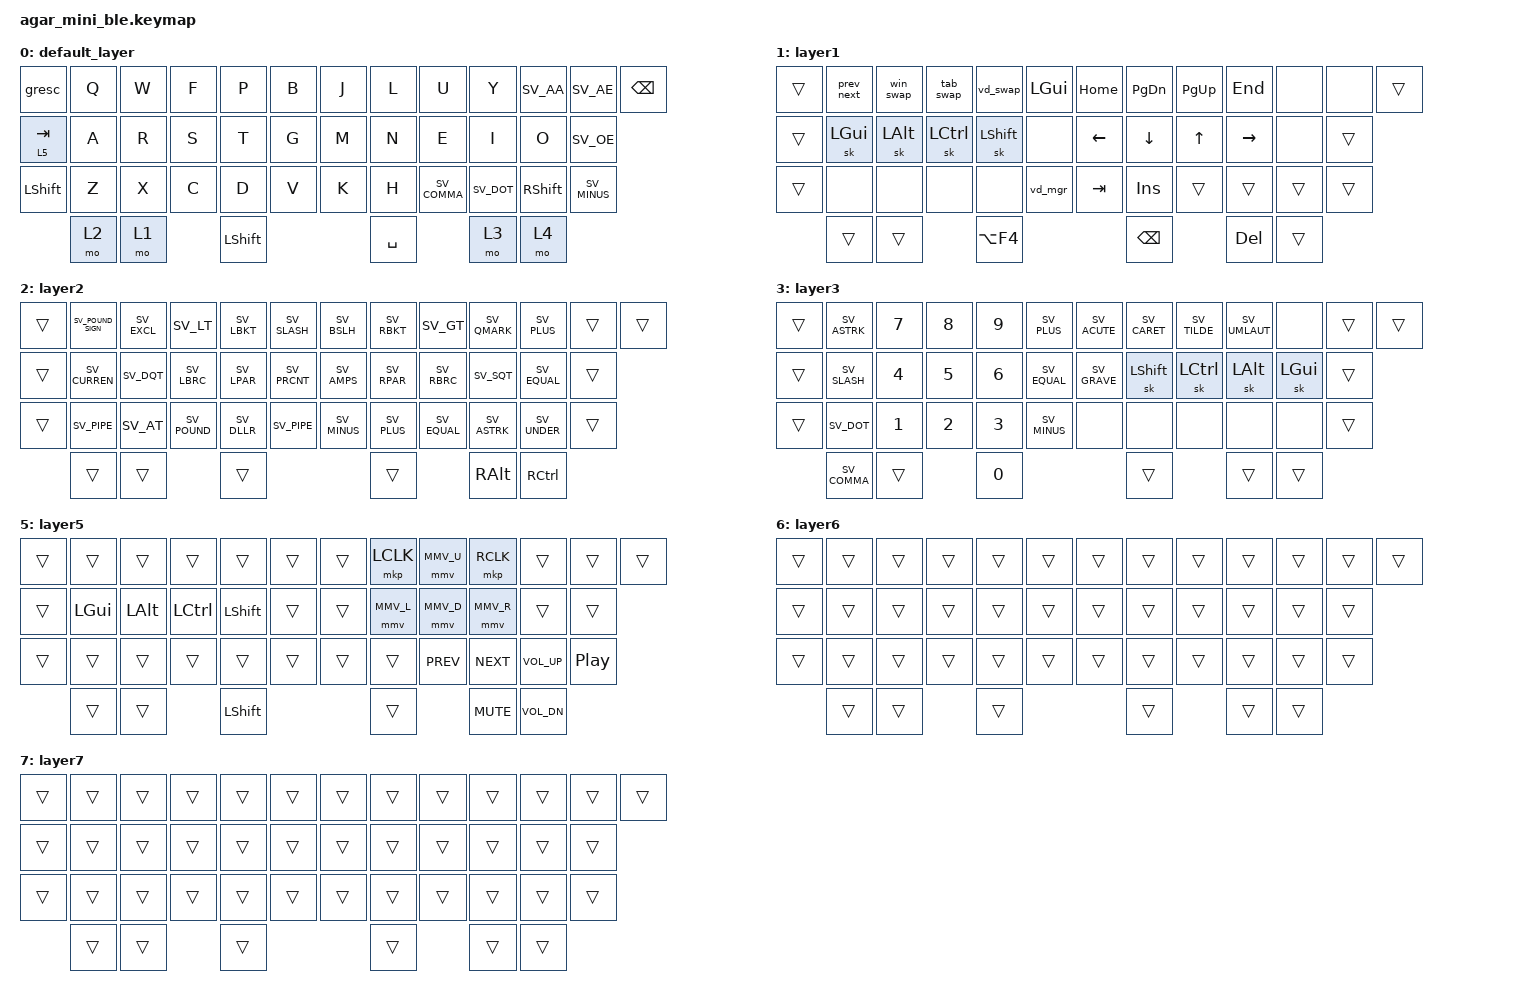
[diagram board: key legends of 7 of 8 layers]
/*
 * Copyright (c) 2021 The ZMK Contributors
 *
 * SPDX-License-Identifier: MIT
 */

#include "./boards/shields/klink_kbd/common.keymap"
#include "keys_sv.h"
#include <behaviors.dtsi>
#include <dt-bindings/zmk/keys.h>
#include <dt-bindings/zmk/pointing.h>

#define SV_AA SV_A_RING
#define SV_AE SV_A_UMLAUT
#define SV_OE SV_O_UMLAUT
#define MMV_L MOVE_LEFT
#define MMV_D MOVE_DOWN
#define MMV_R MOVE_RIGHT
#define MMV_U MOVE_UP

&soft_off {
    hold-time-ms = <3000>;
};

/ {
    combos {
            compatible = "zmk,combos";
            combo_bksp {
                    timeout-ms = <30>;
                    key-positions = <20 21>;
                    bindings = <&kp BACKSPACE>;
            };
            combo_backwards_del {
                    timeout-ms = <45>;
                    key-positions = <20 21 22>;
                    bindings = <&kp LC(BACKSPACE)>;
            };
            combo_backwards_del_term {
                    timeout-ms = <45>;
                    key-positions = <7 8 9>;
                    bindings = <&kp LA(BACKSPACE)>;
            };
            combo_tab {
                    timeout-ms = <25>;
                    key-positions = <16 17>;
                    bindings = <&kp TAB>;
            };
            combo_return {
                    timeout-ms = <50>;
                    key-positions = <22 23>;
                    bindings = <&kp RET>;
            };
    };


    behaviors {
            win_swap: win_swapper {
                    compatible = "zmk,behavior-tri-state";
                    #binding-cells = <0>;
                    bindings = <&kt LALT>, <&kp TAB>, <&kt LALT>;
                    ignored-key-positions = <17 20>;
            };

            tab_swap: tab_swapper {
                    compatible = "zmk,behavior-tri-state";
                    #binding-cells = <0>;
                    bindings = <&kt LCTRL>, <&kp TAB>, <&kt LCTRL>;
                    ignored-key-positions = <17 20>;
            };

            vd_swap: vd_swapper {
                    compatible = "zmk,behavior-mod-morph";
                    #binding-cells = <0>;
                    bindings = <&kp LG(PAGE_DOWN)>, <&kp LG(PAGE_UP)>;
                    mods = <(MOD_LSFT)>;
            };

            vd_mgr: vd_manager {
                    compatible = "zmk,behavior-mod-morph";
                    #binding-cells = <0>;
                    bindings = <&kp LC(LG(D))>, <&kp LC(LG(F4))>;
                    mods = <(MOD_LSFT)>;
            };

            prev_next: previous_next {
                    compatible = "zmk,behavior-mod-morph";
                    #binding-cells = <0>;
                    bindings = <&kp LA(LEFT)>, <&kp LA(RIGHT)>;
                    mods = <(MOD_LSFT)>;
            };
    };

    keymap {
        compatible = "zmk,keymap";

        default_layer {
            bindings = <
&gresc     &kp Q     &kp W     &kp F     &kp P    &kp B     /**/    &kp J     &kp L     &kp U        &kp Y      &kp SV_AA  &kp SV_AE     &kp BSPC
&lt 5 TAB  &kp A     &kp R     &kp S     &kp T    &kp G     /**/    &kp M     &kp N     &kp E        &kp I      &kp O      &kp SV_OE
&kp LSHFT  &kp Z     &kp X     &kp C     &kp D    &kp V     /**/    &kp K     &kp H     &kp SV_COMMA &kp SV_DOT &kp RSHIFT &kp SV_MINUS
           &mo 2     &mo 1               &kp LSHFT                            &kp SPACE              &mo 3      &mo 4
            >;
        };

        layer1 { // NAV
            bindings = <
&trans     &prev_next &win_swap &tab_swap &vd_swap   &kp LGUI /**/  &kp HOME  &kp PG_DN &kp PG_UP  &kp END   &none     &none     &trans
&trans     &sk LGUI   &sk LALT  &sk LCTRL &sk LSHFT  &none    /**/  &kp LEFT  &kp DOWN  &kp UP     &kp RIGHT &none     &trans
&trans     &none      &none     &none     &none      &vd_mgr  /**/  &kp TAB   &kp INS   &trans     &trans    &trans    &trans
           &trans     &trans              &kp LA(F4)                          &kp BSPC             &kp DEL   &trans
            >;
        };

        layer2 { // SYM
            bindings = <
&trans  &kp SV_POUND_SIGN &kp SV_EXCL &kp SV_LT    &kp SV_LBKT &kp SV_SLASH  /**/  &kp SV_BSLH  &kp SV_RBKT &kp SV_GT    &kp SV_QMARK &kp SV_PLUS   &trans     &trans
&trans  &kp SV_CURREN     &kp SV_DQT  &kp SV_LBRC  &kp SV_LPAR &kp SV_PRCNT  /**/  &kp SV_AMPS  &kp SV_RPAR &kp SV_RBRC  &kp SV_SQT   &kp SV_EQUAL  &trans
&trans  &kp SV_PIPE       &kp SV_AT   &kp SV_POUND &kp SV_DLLR &kp SV_PIPE   /**/  &kp SV_MINUS &kp SV_PLUS &kp SV_EQUAL &kp SV_ASTRK &kp SV_UNDER  &trans
        &trans            &trans                   &trans                                       &trans                   &kp RALT     &kp RCTRL
            >;
        };

        layer3 { // NUM
            bindings = <
&trans  &kp SV_ASTRK &kp N7    &kp N8    &kp N9   &kp SV_PLUS   /**/  &kp SV_ACUTE &kp SV_CARET &kp SV_TILDE &kp SV_UMLAUT &none        &trans    &trans
&trans  &kp SV_SLASH &kp N4    &kp N5    &kp N6   &kp SV_EQUAL  /**/  &kp SV_GRAVE &sk LSHFT    &sk LCTRL    &sk LALT      &sk LGUI     &trans
&trans  &kp SV_DOT   &kp N1    &kp N2    &kp N3   &kp SV_MINUS  /**/  &none        &none        &none        &none         &none        &trans
        &kp SV_COMMA &trans              &kp N0                                    &trans                    &trans       &trans
            >;
        };

        layer4 { // FUN
            bindings = <
&none   &none   &kp F7  &kp F8  &kp F9  &kp F10  /**/  &bt BT_SEL 0 &bt BT_SEL 1 &bt BT_SEL 2 &bt BT_SEL 3 &bt BT_SEL 4  &out OUT_BLE  &out OUT_USB
&none   &none   &kp F4  &kp F5  &kp F6  &kp F11  /**/  &soft_off    &sk LSHFT    &sk LCTRL    &sk LALT     &sk LGUI      &trans
&none   &none   &kp F1  &kp F2  &kp F3  &kp F12  /**/  &bootloader  &sys_reset   &bt BT_CLR   &none        &none
        &trans  &trans          &trans                              &trans                    &tog 3       &trans
            >;
        };

        layer5 {
            bindings = <
&trans  &trans   &trans   &trans    &trans    &trans  /**/  &trans  &mkp LCLK  &mmv MMV_U &mkp RCLK   &trans       &trans  &trans
&trans  &kp LGUI &kp LALT &kp LCTRL &kp LSHFT &trans  /**/  &trans  &mmv MMV_L &mmv MMV_D &mmv MMV_R  &trans       &trans
&trans  &trans   &trans   &trans    &trans    &trans  /**/  &trans  &trans     &kp C_PREV &kp C_NEXT  &kp C_VOL_UP &kp C_PLAY_PAUSE
        &trans   &trans             &kp LSHFT                       &trans                &kp C_MUTE  &kp C_VOL_DN
            >;
        };

        layer6 {
            bindings = <
&trans  &trans  &trans  &trans  &trans  &trans  &trans  &trans  &trans  &trans  &trans  &trans  &trans
&trans  &trans  &trans  &trans  &trans  &trans  &trans  &trans  &trans  &trans  &trans  &trans
&trans  &trans  &trans  &trans  &trans  &trans  &trans  &trans  &trans  &trans  &trans  &trans
        &trans  &trans          &trans          &trans                  &trans  &trans
            >;
        };

        layer7 {
            bindings = <
&trans  &trans  &trans  &trans  &trans  &trans  &trans  &trans  &trans  &trans  &trans  &trans  &trans
&trans  &trans  &trans  &trans  &trans  &trans  &trans  &trans  &trans  &trans  &trans  &trans
&trans  &trans  &trans  &trans  &trans  &trans  &trans  &trans  &trans  &trans  &trans  &trans
        &trans  &trans          &trans          &trans                  &trans  &trans
            >;
        };
    };
};
